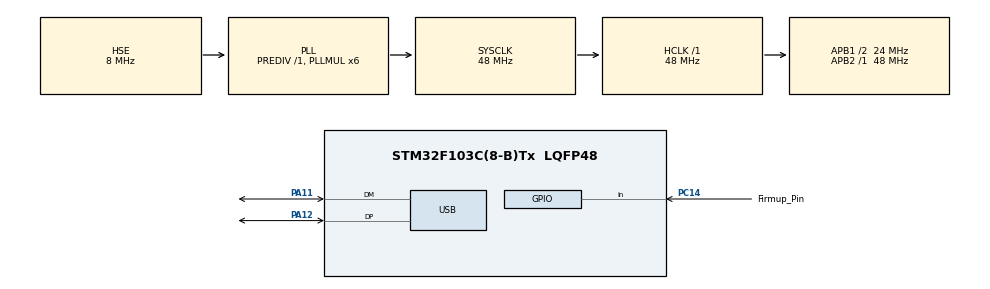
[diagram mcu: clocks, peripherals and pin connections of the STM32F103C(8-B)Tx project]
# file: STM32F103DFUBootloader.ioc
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Mcu.Family=STM32F1
USB_DEVICE.CLASS_NAME_FS=DFU
PD1-OSC_OUT.Mode=HSE-External-Oscillator
USB_DEVICE.VirtualModeFS=Dfu_FS
PA11.Mode=Device
PD0-OSC_IN.Signal=RCC_OSC_IN
RCC.APB1CLKDivider=RCC_HCLK_DIV2
PC14-OSC32_IN.Signal=GPIO_Input
VP_USB_DEVICE_VS_USB_DEVICE_DFU_FS.Mode=DFU_FS
RCC.SYSCLKSource=RCC_SYSCLKSOURCE_PLLCLK
ProjectManager.StackSize=0x400
PD1-OSC_OUT.Signal=RCC_OSC_OUT
PA13.Signal=SYS_JTMS-SWDIO
PA12.Signal=USB_DP
ProjectManager.TargetToolchain=STM32CubeIDE
RCC.HCLKFreq_Value=48000000
RCC.APB2TimFreq_Value=48000000
RCC.USBFreq_Value=48000000
RCC.AHBFreq_Value=48000000
PD0-OSC_IN.Mode=HSE-External-Oscillator
board=custom
RCC.PLLMUL=RCC_PLL_MUL6
RCC.APB2Freq_Value=48000000
USB_DEVICE.USBD_DFU_APP_DEFAULT_ADD=0x08010000
PA14.Mode=Serial_Wire
NVIC.USB_LP_CAN1_RX0_IRQn=true\:0\:0\:false\:false\:true\:false\:true
USB_DEVICE.USBD_DFU_MEDIA=@Internal Flash   /0x08000000/12*001Ka,52*001Kg,64*001Kg
PA13.Mode=Serial_Wire
Mcu.Name=STM32F103C(8-B)Tx
RCC.SYSCLKFreq_VALUE=48000000
Mcu.Package=LQFP48
PA12.Mode=Device
PA11.Signal=USB_DM
PA14.Signal=SYS_JTCK-SWCLK
ProjectManager.HeapSize=0x200
NVIC.PriorityGroup=NVIC_PRIORITYGROUP_4
RCC.APB1TimFreq_Value=48000000
PC14-OSC32_IN.GPIO_Label=Firmup_Pin
RCC.APB1Freq_Value=24000000
USB_DEVICE.VirtualMode=Dfu

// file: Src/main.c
/**
  ******************************************************************************
  * @file           : main.c
  * @brief          : Main program body
  ******************************************************************************
  * This notice applies to any and all portions of this file
  * that are not between comment pairs USER CODE BEGIN and
  * USER CODE END. Other portions of this file, whether
  * inserted by the user or by software development tools
  * are owned by their respective copyright owners.
  *
  * Copyright (c) 2018 STMicroelectronics International N.V.
  * All rights reserved.
  *
  * Redistribution and use in source and binary forms, with or without
  * modification, are permitted, provided that the following conditions are met:
  *
  * 1. Redistribution of source code must retain the above copyright notice,
  *    this list of conditions and the following disclaimer.
  * 2. Redistributions in binary form must reproduce the above copyright notice,
  *    this list of conditions and the following disclaimer in the documentation
  *    and/or other materials provided with the distribution.
  * 3. Neither the name of STMicroelectronics nor the names of other
  *    contributors to this software may be used to endorse or promote products
  *    derived from this software without specific written permission.
  * 4. This software, including modifications and/or derivative works of this
  *    software, must execute solely and exclusively on microcontroller or
  *    microprocessor devices manufactured by or for STMicroelectronics.
  * 5. Redistribution and use of this software other than as permitted under
  *    this license is void and will automatically terminate your rights under
  *    this license.
  *
  * THIS SOFTWARE IS PROVIDED BY STMICROELECTRONICS AND CONTRIBUTORS "AS IS"
  * AND ANY EXPRESS, IMPLIED OR STATUTORY WARRANTIES, INCLUDING, BUT NOT
  * LIMITED TO, THE IMPLIED WARRANTIES OF MERCHANTABILITY, FITNESS FOR A
  * PARTICULAR PURPOSE AND NON-INFRINGEMENT OF THIRD PARTY INTELLECTUAL PROPERTY
  * RIGHTS ARE DISCLAIMED TO THE FULLEST EXTENT PERMITTED BY LAW. IN NO EVENT
  * SHALL STMICROELECTRONICS OR CONTRIBUTORS BE LIABLE FOR ANY DIRECT, INDIRECT,
  * INCIDENTAL, SPECIAL, EXEMPLARY, OR CONSEQUENTIAL DAMAGES (INCLUDING, BUT NOT
  * LIMITED TO, PROCUREMENT OF SUBSTITUTE GOODS OR SERVICES; LOSS OF USE, DATA,
  * OR PROFITS; OR BUSINESS INTERRUPTION) HOWEVER CAUSED AND ON ANY THEORY OF
  * LIABILITY, WHETHER IN CONTRACT, STRICT LIABILITY, OR TORT (INCLUDING
  * NEGLIGENCE OR OTHERWISE) ARISING IN ANY WAY OUT OF THE USE OF THIS SOFTWARE,
  * EVEN IF ADVISED OF THE POSSIBILITY OF SUCH DAMAGE.
  *
  ******************************************************************************
  */
#include "main.h"

/* USER CODE BEGIN Includes */
#include "usb_device.h"

/* USER CODE END Includes */

/* USER CODE BEGIN PV */
/* Private variables ---------------------------------------------------------*/

/* USER CODE END PV */

void SystemClock_Config(void);
static void MX_GPIO_Init(void);

/* USER CODE BEGIN PFP */
/* Private function prototypes -----------------------------------------------*/

/* USER CODE END PFP */

int main(void)
{
  /* USER CODE BEGIN 1 */
  typedef  void (*pFunction)(void);
  uint32_t JumpAddress;
  void (*Jump_To_Application)();
  /* USER CODE END 1 */

  /* MCU Configuration----------------------------------------------------------*/

  /* Reset of all peripherals, Initializes the Flash interface and the Systick. */
  HAL_Init();

  /* Configure the system clock */
  SystemClock_Config();

  /* Initialize all configured peripherals */
  MX_GPIO_Init();
  /* USER CODE BEGIN 2 */
  if (HAL_GPIO_ReadPin(Firmup_Pin_GPIO_Port, Firmup_Pin_Pin) != GPIO_PIN_RESET)
  {
    if (((*(__IO uint32_t*)USBD_DFU_APP_DEFAULT_ADD - 1) & 0x2FFFB000 ) == 0x20000000)
    {
      JumpAddress = *(__IO uint32_t*) (USBD_DFU_APP_DEFAULT_ADD + 4);
      Jump_To_Application = (pFunction) JumpAddress;
      __set_MSP(*(__IO uint32_t*) USBD_DFU_APP_DEFAULT_ADD);
      Jump_To_Application();
    }
  }
  MX_USB_DEVICE_Init();

  /* USER CODE END 2 */

  /* Infinite loop */
  while (1)
  {

  }

}

void SystemClock_Config(void)
{

  RCC_OscInitTypeDef RCC_OscInitStruct;
  RCC_ClkInitTypeDef RCC_ClkInitStruct;
  RCC_PeriphCLKInitTypeDef PeriphClkInit;

    /**Initializes the CPU, AHB and APB busses clocks
    */
  RCC_OscInitStruct.OscillatorType = RCC_OSCILLATORTYPE_HSE;
  RCC_OscInitStruct.HSEState = RCC_HSE_ON;
  RCC_OscInitStruct.HSEPredivValue = RCC_HSE_PREDIV_DIV1;
  RCC_OscInitStruct.HSIState = RCC_HSI_ON;
  RCC_OscInitStruct.PLL.PLLState = RCC_PLL_ON;
  RCC_OscInitStruct.PLL.PLLSource = RCC_PLLSOURCE_HSE;
  RCC_OscInitStruct.PLL.PLLMUL = RCC_PLL_MUL6;
  if (HAL_RCC_OscConfig(&RCC_OscInitStruct) != HAL_OK)
  {
    _Error_Handler(__FILE__, __LINE__);
  }

    /**Initializes the CPU, AHB and APB busses clocks
    */
  RCC_ClkInitStruct.ClockType = RCC_CLOCKTYPE_HCLK|RCC_CLOCKTYPE_SYSCLK
                              |RCC_CLOCKTYPE_PCLK1|RCC_CLOCKTYPE_PCLK2;
  RCC_ClkInitStruct.SYSCLKSource = RCC_SYSCLKSOURCE_PLLCLK;
  RCC_ClkInitStruct.AHBCLKDivider = RCC_SYSCLK_DIV1;
  RCC_ClkInitStruct.APB1CLKDivider = RCC_HCLK_DIV2;
  RCC_ClkInitStruct.APB2CLKDivider = RCC_HCLK_DIV1;

  if (HAL_RCC_ClockConfig(&RCC_ClkInitStruct, FLASH_LATENCY_1) != HAL_OK)
  {
    _Error_Handler(__FILE__, __LINE__);
  }

  PeriphClkInit.PeriphClockSelection = RCC_PERIPHCLK_USB;
  PeriphClkInit.UsbClockSelection = RCC_USBCLKSOURCE_PLL;
  if (HAL_RCCEx_PeriphCLKConfig(&PeriphClkInit) != HAL_OK)
  {
    _Error_Handler(__FILE__, __LINE__);
  }

    /**Configure the Systick interrupt time
    */
  HAL_SYSTICK_Config(HAL_RCC_GetHCLKFreq()/1000);

    /**Configure the Systick
    */
  HAL_SYSTICK_CLKSourceConfig(SYSTICK_CLKSOURCE_HCLK);

  /* SysTick_IRQn interrupt configuration */
  HAL_NVIC_SetPriority(SysTick_IRQn, 0, 0);
}

/** Configure pins as
        * Analog
        * Input
        * Output
        * EVENT_OUT
        * EXTI
*/
static void MX_GPIO_Init(void)
{

  GPIO_InitTypeDef GPIO_InitStruct;

  /* GPIO Ports Clock Enable */
  __HAL_RCC_GPIOC_CLK_ENABLE();
  __HAL_RCC_GPIOD_CLK_ENABLE();
  __HAL_RCC_GPIOA_CLK_ENABLE();

  /*Configure GPIO pin : Firmup_Pin_Pin */
  GPIO_InitStruct.Pin = Firmup_Pin_Pin;
  GPIO_InitStruct.Mode = GPIO_MODE_INPUT;
  GPIO_InitStruct.Pull = GPIO_NOPULL;
  HAL_GPIO_Init(Firmup_Pin_GPIO_Port, &GPIO_InitStruct);

}

void _Error_Handler(char *file, int line)
{
  while(1)
  {
  }
}

/************************ (C) COPYRIGHT STMicroelectronics *****END OF FILE****/
